# ATSAM3U4E register map
Vendor: Atmel; File version: 0
CPU: CM3 r2p0, selectable endian, no MPU, no FPU, 0x4 interrupt priority bits, 0x0 interrupts
Registers are 32-bit, read-write, no defined reset value unless marked. A register's access mark holds for its fields unless they carry their own. Offsets are from the block's base; [hi:lo] are bit positions; {n}, {i} and the like mark numbered series.

## ADC12B — Analog-to-Digital Converter 12bits
Base 0x400A8000; register names take the prefix ADC12B_
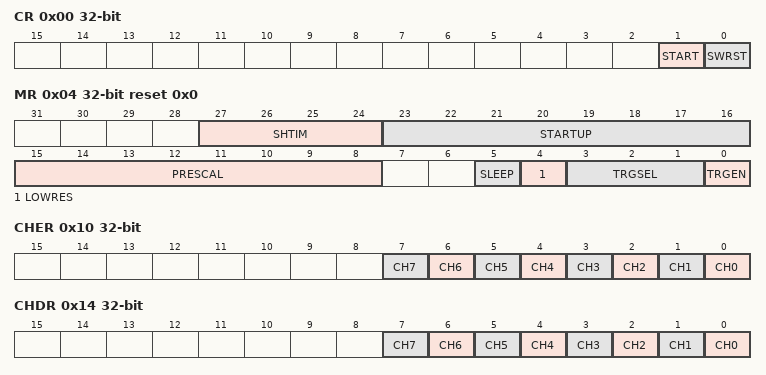
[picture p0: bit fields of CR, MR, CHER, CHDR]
0x00 CR wo — Control Register
  [1] START — Start Conversion
  [0] SWRST — Software Reset
0x04 MR reset 0x0 — Mode Register
  [27:24] SHTIM — Sample & Hold Time
  [23:16] STARTUP — Start Up Time
  [15:8] PRESCAL — Prescaler Rate Selection
  [5] SLEEP — Sleep Mode
  [4] LOWRES — Resolution
  [3:1] TRGSEL — Trigger Selection
  [0] TRGEN — Trigger Enable
0x10 CHER wo — Channel Enable Register
  [n] CH{n} (n=0..7) — Channel {n} Enable
0x14 CHDR wo — Channel Disable Register
  [n] CH{n} (n=0..7)
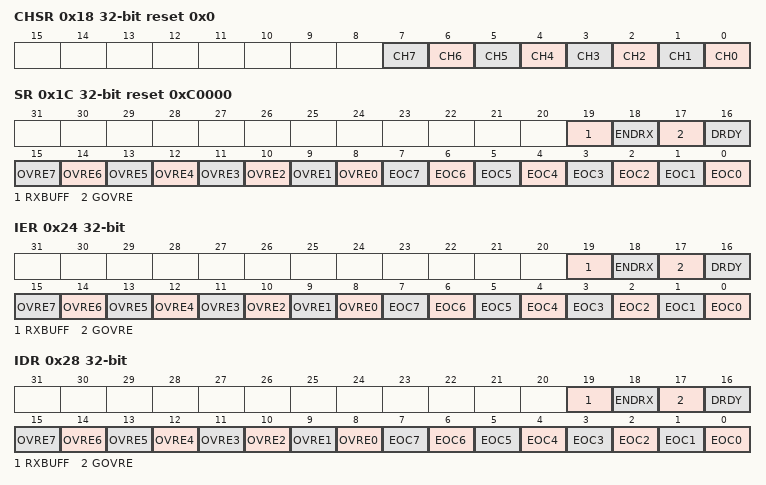
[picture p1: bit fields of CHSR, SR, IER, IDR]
0x18 CHSR ro reset 0x0 — Channel Status Register
  [n] CH{n} (n=0..7) — Channel {n} Status
0x1C SR ro reset 0xC0000 — Status Register
  [19] RXBUFF — RX Buffer Full
  [18] ENDRX — End of RX Buffer
  [17] GOVRE — General Overrun Error
  [16] DRDY — Data Ready
  [n+8] OVRE{n} (n=0..7) — Overrun Error {n}
  [n] EOC{n} (n=0..7) — End of Conversion {n}
0x20 LCDR ro reset 0x0 — Last Converted Data Register
  [11:0] LDATA — Last Data Converted
0x24 IER wo — Interrupt Enable Register
  [19] RXBUFF — Receive Buffer Full Interrupt Enable
  [18] ENDRX — End of Receive Buffer Interrupt Enable
  [17] GOVRE — General Overrun Error Interrupt Enable
  [16] DRDY — Data Ready Interrupt Enable
  [n+8] OVRE{n} (n=0..7) — Overrun Error Interrupt Enable {n}
  [n] EOC{n} (n=0..7) — End of Conversion Interrupt Enable {n}
0x28 IDR wo — Interrupt Disable Register
  [19] RXBUFF — Receive Buffer Full Interrupt Disable
  [18] ENDRX — End of Receive Buffer Interrupt Disable
  [17] GOVRE — General Overrun Error Interrupt Disable
  [16] DRDY — Data Ready Interrupt Disable
  [n+8] OVRE{n} (n=0..7) — Overrun Error Interrupt Disable {n}
  [n] EOC{n} (n=0..7) — End of Conversion Interrupt Disable {n}
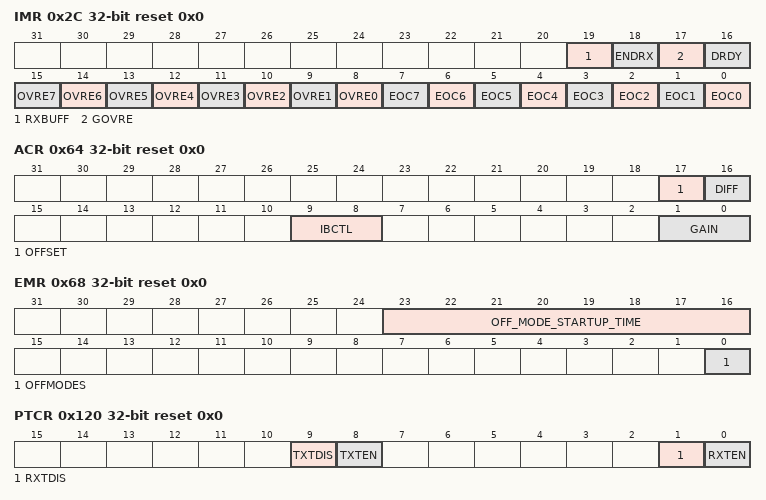
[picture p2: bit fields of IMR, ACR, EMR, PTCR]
0x2C IMR ro reset 0x0 — Interrupt Mask Register
  [19] RXBUFF — Receive Buffer Full Interrupt Mask
  [18] ENDRX — End of Receive Buffer Interrupt Mask
  [17] GOVRE — General Overrun Error Interrupt Mask
  [16] DRDY — Data Ready Interrupt Mask
  [n+8] OVRE{n} (n=0..7) — Overrun Error Interrupt Mask {n}
  [n] EOC{n} (n=0..7) — End of Conversion Interrupt Mask {n}
{0x30+4i} CDR[{i}] ro (i=0..7) — Channel Data Register
  [11:0] DATA — Converted Data
0x64 ACR reset 0x0 — Analog Control Register
  [17] OFFSET — Input OFFSET
  [16] DIFF — Differential Mode
  [9:8] IBCTL — Bias Current Control
  [1:0] GAIN — Input Gain
0x68 EMR reset 0x0 — Extended Mode Register
  [23:16] OFF_MODE_STARTUP_TIME — Startup Time
  [0] OFFMODES — Off Mode if Sleep Bit (ADC12B_MR) = 1
0x100 RPR reset 0x0 — Receive Pointer Register
  [31:0] RXPTR
0x104 RCR reset 0x0 — Receive Counter Register
  [15:0] RXCTR
0x110 RNPR reset 0x0 — Receive Next Pointer Register
  [31:0] RXNPTR — Receive Next Pointer
0x114 RNCR reset 0x0 — Receive Next Counter Register
  [15:0] RXNCTR — Receive Next Counter
0x120 PTCR wo reset 0x0 — Transfer Control Register
  [9] TXTDIS — Transmitter Transfer Disable
  [8] TXTEN — Transmitter Transfer Enable
  [1] RXTDIS — Receiver Transfer Disable
  [0] RXTEN — Receiver Transfer Enable
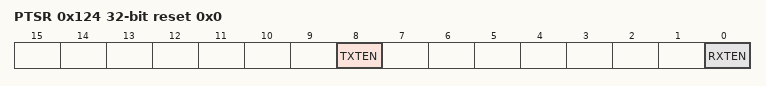
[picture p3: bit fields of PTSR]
0x124 PTSR ro reset 0x0 — Transfer Status Register
  [8] TXTEN — Transmitter Transfer Enable
  [0] RXTEN — Receiver Transfer Enable

## ADC — Analog-to-Digital Converter
Base 0x400AC000; register names take the prefix ADC_
Registers as ADC12B, without ACR, EMR; these are added or differ:
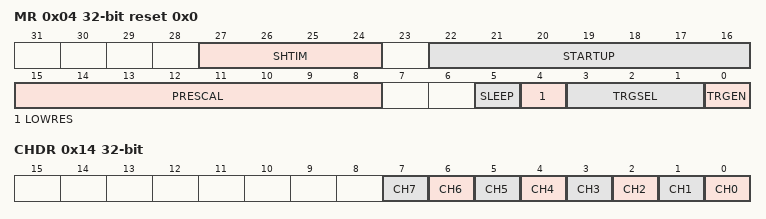
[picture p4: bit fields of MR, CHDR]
0x04 MR reset 0x0 — Mode Register
  [27:24] SHTIM — Sample & Hold Time
  [22:16] STARTUP — Start Up Time
  [15:8] PRESCAL — Prescaler Rate Selection
  [5] SLEEP — Sleep Mode
  [4] LOWRES — Resolution
  [3:1] TRGSEL — Trigger Selection
  [0] TRGEN — Trigger Enable
0x14 CHDR wo — Channel Disable Register
  [n] CH{n} (n=0..7) — Channel {n} Disable
0x20 LCDR ro reset 0x0 — Last Converted Data Register
  [9:0] LDATA — Last Data Converted
{0x30+4i} CDR[{i}] ro (i=0..7) — Channel Data Register
  [9:0] DATA — Converted Data
